# RA2A1 register map
Vendor: Renesas Electronics Corporation; Series: RA2; File version: 1.1
CPU: other r1p0, little endian, MPU, no FPU, VTOR, 2 interrupt priority bits
Registers are 8-bit, read-write, reset 0x0 unless marked. A register's access mark holds for its fields unless they carry their own. Offsets are from the block's base; [hi:lo] are bit positions; {n}, {i} and the like mark numbered series; 'fields as' and 'values as' point back to an identical list.

## CAN0 — CAN0 Module
Base 0x40050000
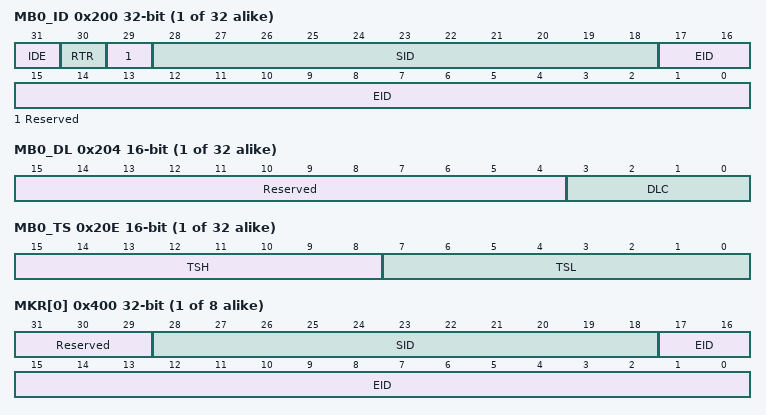
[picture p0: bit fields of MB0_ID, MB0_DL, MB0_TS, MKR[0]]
{0x200+0x10*i} MB{i}_ID (i=0..31) 32-bit reset not defined — Mailbox Register
  [31] IDE — ID Extension
    0=Standard ID; 1=Extended ID
  [30] RTR — Remote Transmission Request
    0=Data frame; 1=Remote frame
  [29] Reserved — This bit is read as 0. The write value should be 0.
  [28:18] SID — Standard ID
    0=Corresponding SID[10:0] bits are 0; 1=Corresponding SID[10:0] bits are 1
  [17:0] EID — Extended ID
    0=Corresponding EID[17:0] bits are 0; 1=Corresponding EID[17:0] bits are 1
{0x204+0x10*i} MB{i}_DL (i=0..31) 16-bit reset not defined — Mailbox Register
  [15:4] Reserved — These bits are read as 000000000000. The write value should be 000000000000.
  [3:0] DLC — Data Length Code
    0=Data length = 0 byte; 1=Data length = 1 byte; {v}=Data length = {v} bytes (v=2..7); other=others (Data length = 8 bytes)
{0x206+0x10*i} MB{i}_D0 (i=0..31) reset not defined — Mailbox Register
  [7:0] DATA0 — Data Bytes 0.DATA0 store the transmitted or received CAN message data. Transmission or reception starts from DATA0. The bit order on the CAN bus is MSB first, and transmission or reception starts from bit 7.
{0x207+0x10*i} MB{i}_D1 (i=0..31) reset not defined — Mailbox Register
  [7:0] DATA1 — Data Bytes 1DATA1 store the transmitted or received CAN message data. Transmission or reception starts from DATA0. The bit order on the CAN bus is MSB first, and transmission or reception starts from bit 7.
{0x208+0x10*i} MB{i}_D2 (i=0..31) reset not defined — Mailbox Register
  [7:0] DATA2 — Data Bytes 2DATA2 store the transmitted or received CAN message data. Transmission or reception starts from DATA0. The bit order on the CAN bus is MSB first, and transmission or reception starts from bit 7.
{0x209+0x10*i} MB{i}_D3 (i=0..31) reset not defined — Mailbox Register
  [7:0] DATA3 — Data Bytes 3DATA3 store the transmitted or received CAN message data. Transmission or reception starts from DATA0. The bit order on the CAN bus is MSB first, and transmission or reception starts from bit 7.
{0x20A+0x10*i} MB{i}_D4 (i=0..31) reset not defined — Mailbox Register
  [7:0] DATA4 — Data Bytes 4DATA4 store the transmitted or received CAN message data. Transmission or reception starts from DATA0. The bit order on the CAN bus is MSB first, and transmission or reception starts from bit 7.
{0x20B+0x10*i} MB{i}_D5 (i=0..31) reset not defined — Mailbox Register
  [7:0] DATA5 — Data Bytes 5DATA5 store the transmitted or received CAN message data. Transmission or reception starts from DATA0. The bit order on the CAN bus is MSB first, and transmission or reception starts from bit 7.
{0x20C+0x10*i} MB{i}_D6 (i=0..31) reset not defined — Mailbox Register
  [7:0] DATA6 — Data Bytes 6DATA6 store the transmitted or received CAN message data. Transmission or reception starts from DATA0. The bit order on the CAN bus is MSB first, and transmission or reception starts from bit 7.
{0x20D+0x10*i} MB{i}_D7 (i=0..31) reset not defined — Mailbox Register
  [7:0] DATA7 — Data Bytes 7DATA7 store the transmitted or received CAN message data. Transmission or reception starts from DATA0. The bit order on the CAN bus is MSB first, and transmission or reception starts from bit 7.
{0x20E+0x10*i} MB{i}_TS (i=0..31) 16-bit reset not defined — Mailbox Register
  [15:8] TSH — Time Stamp Lower ByteBits TSH[7:0] store the counter value of the time stamp when received messages are stored in the mailbox.
  [7:0] TSL — Time Stamp Higher ByteBits TSL[7:0] store the counter value of the time stamp when received messages are stored in the mailbox.
{0x400+4i} MKR[{i}] (i=0..7) 32-bit reset not defined — Mask Register
  [31:29] Reserved — These bits are read as 000. The write value should be 000.
  [28:18] SID — Standard ID
    0=Corresponding SID[10:0] bit is not compared; 1=Corresponding SID[10:0] bit is compared
  [17:0] EID — Extended ID
    0=Corresponding EID[17:0] bit is not compared; 1=Corresponding EID[17:0] bit is compared
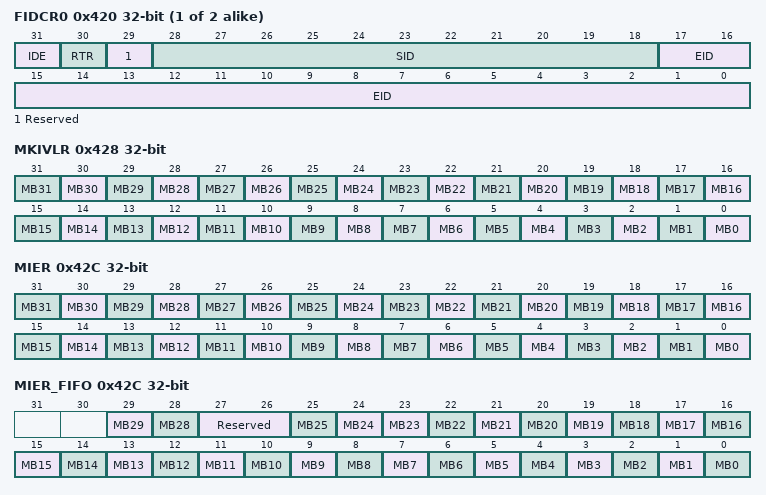
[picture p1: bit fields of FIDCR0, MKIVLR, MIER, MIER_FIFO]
{0x420+4i} FIDCR{i} (i=0..1) 32-bit reset not defined — FIFO Received ID Compare Registers
  fields as MB0_ID
0x428 MKIVLR 32-bit reset not defined — Mask Invalid Register
  [all] fields
    0=Mask valid; 1=Mask invalid
  [n] MB{n} (n=0..31) — mailbox {n} Mask Invalid
0x42C MIER 32-bit reset not defined — Mailbox Interrupt Enable Register (Normal mailbox mode)
  [all] fields
    0=Interrupt disabled; 1=Interrupt enabled
  [n] MB{n} (n=0..31) — mailbox {n} Interrupt Enable
0x42C MIER_FIFO 32-bit reset not defined (alternate view of MIER) — Mailbox Interrupt Enable Register(FIFO mailbox mode)
  [29] MB29 — Receive FIFO Interrupt Generation Timing Control
    0=Every time reception is completed; 1=When the receive FIFO becomes buffer warning by completion of reception
  [28] MB28 — Receive FIFO Interrupt Enable
    0=Interrupt disabled; 1=Interrupt enabled
  [27:26] Reserved — These bits are read as 00. The write value should be 00.
  [25] MB25 — Transmit FIFO Interrupt Generation Timing Control
    0=Every time transmission is completed; 1=When the transmit FIFO becomes empty due to completion of transmission
  [24] MB24 — Transmit FIFO Interrupt Enable
    0=Interrupt disabled; 1=Interrupt enabled
  [n] MB{n} (n=0..23) — mailbox {n} Interrupt Enable
    0=Interrupt disabled; 1=Interrupt enabled
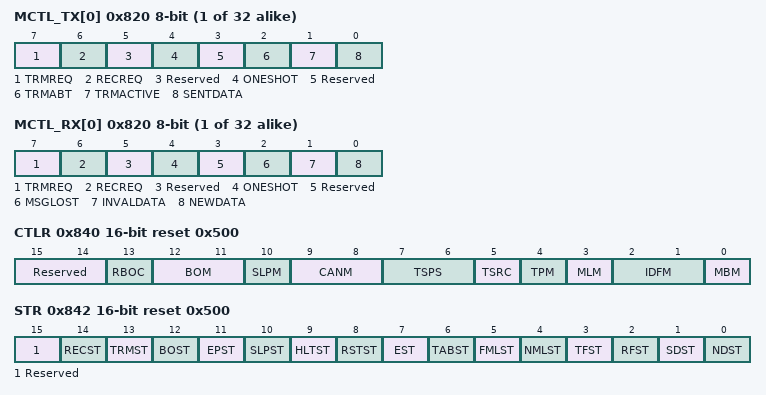
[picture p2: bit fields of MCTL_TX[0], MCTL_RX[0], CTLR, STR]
{0x820+i} MCTL_TX[{i}] (i=0..31) — Message Control Register(Transmit mode (when the TRMREQ bit is 1 and the RECREQ bit is 0))
  [7] TRMREQ — Transmit Mailbox Request
    0=Not configured for transmission; 1=Configured for transmission
  [6] RECREQ — Receive Mailbox Request
    0=Not configured for reception; 1=Configured for reception
  [5] Reserved — This bit is read as 0. The write value should be 0.
  [4] ONESHOT — One-Shot Enable
    0=One-shot reception or one-shot transmission disabled; 1=One-shot reception or one-shot transmission enabled
  [3] Reserved — This bit is read as 0. The write value should be 0.
  [2] TRMABT — Transmission Abort Complete Flag (Transmit mailbox setting enabled)
    0=Transmission has started, transmission abort failed because transmission is completed, or transmission abort is not requested; 1=Transmission abort is completed
  [1] TRMACTIVE ro — Transmission-in-Progress Status Flag (Transmit mailbox setting enabled)
    0=Transmission is pending or transmission is not requested; 1=From acceptance of transmission request to completion of transmission, or error/arbitration-lost
  [0] SENTDATA — Transmission Complete Flag
    0=Transmission is not completed; 1=Transmission is completed
{0x820+i} MCTL_RX[{i}] (i=0..31) (alternate view of MCTL_TX[{i}]) — Message Control Register( Receive mode (when the TRMREQ bit is 0 and the RECREQ bit is 1))
  [7] TRMREQ — Transmit Mailbox Request
    values as MCTL_TX[0].TRMREQ
  [6] RECREQ — Receive Mailbox Request
    0=Not configured for reception; 1=Configured for reception
  [5] Reserved — This bit is read as 0. The write value should be 0.
  [4] ONESHOT — One-Shot Enable
    values as MCTL_TX[0].ONESHOT
  [3] Reserved — This bit is read as 0. The write value should be 0.
  [2] MSGLOST — Message Lost Flag(Receive mailbox setting enabled)
    0=Message is not overwritten or overrun; 1=Message is overwritten or overrun
  [1] INVALDATA ro — Reception-in-Progress Status Flag (Receive mailbox setting enabled)
    0=Message valid; 1=Message being updated
  [0] NEWDATA — Reception Complete Flag
    0=No data has been received or 0 is written to the NEWDATA bit; 1=A new message is being stored or has been stored to the mailbox
0x840 CTLR 16-bit reset 0x500 — Control Register
  [15:14] Reserved — These bits are read as 00. The write value should be 00.
  [13] RBOC — Forcible Return From Bus-Off
    0=Nothing occurred; 1=Forcible return from bus-off
  [12:11] BOM — Bus-Off Recovery Mode
    0=Normal mode (ISO11898-1 compliant); 1=Entry to CAN halt mode automatically at bus-off entry; 2=Entry to CAN halt mode automatically at bus-off end; 3=Entry to CAN halt mode (during bus-off recovery period) by a program request
  [10] SLPM — CAN Sleep Mode
    0=Other than CAN sleep mode; 1=CAN sleep mode
  [9:8] CANM — CAN Mode of Operation Select
    0=CAN operation mode; 1=CAN reset mode; 2=CAN halt mode; 3=CAN reset mode (forcible transition)
  [7:6] TSPS — Time Stamp Prescaler Select
    0=Every bit time; 1=Every 2-bit time; 2=Every 4-bit time; 3=Every 8-bit time
  [5] TSRC — Time Stamp Counter Reset Command
    0=Nothing occurred; 1=Reset
  [4] TPM — Transmission Priority Mode Select
    0=ID priority transmit mode; 1=Mailbox number priority transmit mode
  [3] MLM — Message Lost Mode Select
    0=Overwrite mode; 1=Overrun mode
  [2:1] IDFM — ID Format Mode Select
    0=Standard ID mode.All mailboxes (including FIFO mailboxes) handle only standard Ids; 1=Extended ID mode.All mailboxes (including FIFO mailboxes) handle only extended IDs; 2=Mixed ID mode.All mailboxes (including FIFO mailboxes) handle both standard IDs and extended IDs. Standard IDs or extended IDs are specified by using the IDE bit in the corresponding mailbox in normal mailbox mode. In FIFO mailbox mode, the IDE bit in the corresponding mailbox is used for mailboxes [0] to [23], the IDE bits in FIDCR0 and FIDCR1 are used for the receive FIFO, and the IDE bit in mailbox [24] is used for the transmit FIFO.; 3=Do not use this combination
  [0] MBM — CAN Mailbox Mode Select
    0=Normal mailbox mode; 1=FIFO mailbox mode
0x842 STR 16-bit ro reset 0x500 — Status Register
  [15] Reserved — This bit is read as 0.
  [14] RECST — Receive Status Flag (receiver)
    0=Bus idle or transmission in progress; 1=Reception in progress
  [13] TRMST — Transmit Status Flag (transmitter)
    0=Bus idle or reception in progress; 1=Transmission in progress or in bus-off state
  [12] BOST — Bus-Off Status Flag
    0=Not in bus-off state; 1=In bus-off state
  [11] EPST — Error-Passive Status Flag
    0=Not in error-passive state; 1=In error-passive state
  [10] SLPST — CAN Sleep Status Flag
    0=Not in CAN sleep mode; 1=In CAN sleep mode
  [9] HLTST — CAN Halt Status Flag
    0=Not in CAN halt mode; 1=In CAN halt mode
  [8] RSTST — CAN Reset Status Flag
    0=Not in CAN reset mode; 1=In CAN reset mode
  [7] EST — Error Status Flag
    0=No error occurred; 1=Error occurred
  [6] TABST — Transmission Abort Status Flag
    0=No mailbox with TRMABT bit = 1; 1=Mailbox(es) with TRMABT bit = 1
  [5] FMLST — FIFO Mailbox Message Lost Status Flag
    0=RFMLF bit = 0; 1=RFMLF bit = 1
  [4] NMLST — Normal Mailbox Message Lost Status Flag
    0=No mailbox with MSGLOST bit = 1; 1=Mailbox(es) with MSGLOST bit = 1
  [3] TFST — Transmit FIFO Status Flag
    0=Transmit FIFO is full; 1=Transmit FIFO is not full
  [2] RFST — Receive FIFO Status Flag
    0=No message in receive FIFO (empty); 1=Message in receive FIFO
  [1] SDST — SENTDATA Status Flag
    0=No mailbox with SENTDATA bit = 1; 1=Mailbox(es) with SENTDATA bit = 1
  [0] NDST — NEWDATA Status Flag
    0=No mailbox with NEWDATA bit = 1; 1=Mailbox(es) with NEWDATA bit = 1
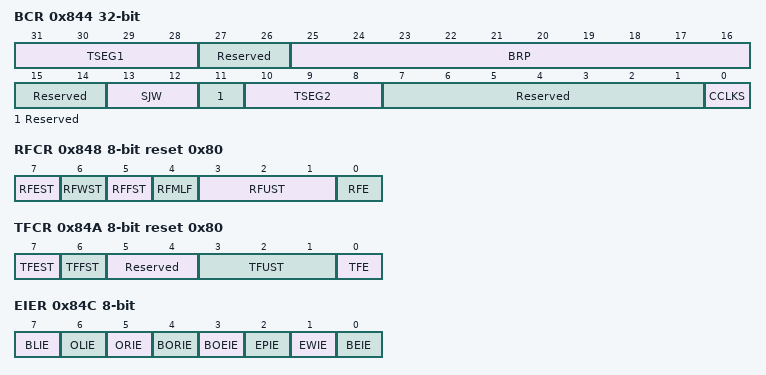
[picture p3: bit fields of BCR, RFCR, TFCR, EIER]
0x844 BCR 32-bit — Bit Configuration Register
  [31:28] TSEG1 — Time Segment 1 Control
    {v}={v+1} Tq (v=3..15); other=others (Setting prohibited)
  [27:26] Reserved — These bits are read as 00. The write value should be 00.
  [25:16] BRP — Baud Rate Prescaler select . These bits set the frequency of the CAN communication clock (fCANCLK).
  [15:14] Reserved — These bits are read as 00. The write value should be 00.
  [13:12] SJW — Resynchronization Jump Width Control
    {v}={v+1} Tq (v=0..3)
  [11] Reserved — This bit is read as 0. The write value should be 0.
  [10:8] TSEG2 — Time Segment 2 Control
    0=Setting prohibited; {v}={v+1} Tq (v=1..7)
  [7:1] Reserved — These bits are read as 0000000. The write value should be 0000000.
  [0] CCLKS — CAN Clock Source Selection
    0=PCLK (generated by the PLL clock); 1=CANMCLK (generated by the main clock)
0x848 RFCR reset 0x80 — Receive FIFO Control Register
  [7] RFEST ro — Receive FIFO Empty Status Flag
    0=Unread message in receive FIFO; 1=No unread message in receive FIFO
  [6] RFWST ro — Receive FIFO Buffer Warning Status Flag
    0=Receive FIFO is not buffer warning; 1=Receive FIFO is buffer warning (3 unread messages)
  [5] RFFST ro — Receive FIFO Full Status Flag
    0=Receive FIFO is not full; 1=Receive FIFO is full (4 unread messages)
  [4] RFMLF — Receive FIFO Message Lost Flag
    0=No receive FIFO message lost has occurred; 1=Receive FIFO message lost has occurred
  [3:1] RFUST ro — Receive FIFO Unread Message Number Status
    0=No unread message; 1=1 unread message; 2=2 unread messages; 3=3 unread messages; 4=4 unread messages; other=others (Setting prohibited)
  [0] RFE — Receive FIFO Enable
    0=Receive FIFO disabled; 1=Receive FIFO enabled
0x849 RFPCR wo reset not defined — Receive FIFO Pointer Control Register
  [7:0] RFPCR — The CPU-side pointer for the receive FIFO is incremented by writing FFh to RFPCR.
0x84A TFCR reset 0x80 — Transmit FIFO Control Register
  [7] TFEST ro — Transmit FIFO Empty Status
    0=Unsent message in transmit FIFO; 1=No unsent message in transmit FIFO
  [6] TFFST ro — Transmit FIFO Full Status
    0=Transmit FIFO is not full; 1=Transmit FIFO is full (4 unsent messages)
  [5:4] Reserved — These bits are read as 00. The write value should be 00.
  [3:1] TFUST ro — Transmit FIFO Unsent Message Number Status
    0=No unsent message; 1=1 unsent message; 2=2 unsent messages; 3=3 unsent messages; 4=4 unsent messages; other=others (Setting prohibited)
  [0] TFE — Transmit FIFO Enable
    0=Transmit FIFO disabled; 1=Transmit FIFO enabled
0x84B TFPCR wo reset not defined — Transmit FIFO Pointer Control Register
  [7:0] TFPCR — The CPU-side pointer for the transmit FIFO is incremented by writing FFh to TFPCR.
0x84C EIER — Error Interrupt Enable Register
  [7] BLIE — Bus Lock Interrupt Enable
    0=Bus lock interrupt disabled; 1=Bus lock interrupt enabled
  [6] OLIE — Overload Frame Transmit Interrupt Enable
    0=Overload frame transmit interrupt disabled; 1=Overload frame transmit interrupt enabled
  [5] ORIE — Overrun Interrupt Enable
    0=Receive overrun interrupt disabled; 1=Receive overrun interrupt enabled
  [4] BORIE — Bus-Off Recovery Interrupt Enable
    0=Bus-off recovery interrupt disabled; 1=Bus-off recovery interrupt enabled
  [3] BOEIE — Bus-Off Entry Interrupt Enable
    0=Bus-off entry interrupt disabled; 1=Bus-off entry interrupt enabled
  [2] EPIE — Error-Passive Interrupt Enable
    0=Error-passive interrupt disabled; 1=Error-passive interrupt enabled
  [1] EWIE — Error-Warning Interrupt Enable
    0=Error-warning interrupt disabled; 1=Error-warning interrupt enabled
  [0] BEIE — Bus Error Interrupt Enable
    0=Bus error interrupt disabled; 1=Bus error interrupt enabled
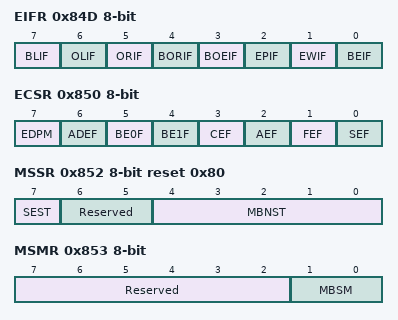
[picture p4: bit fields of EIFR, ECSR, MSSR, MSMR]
0x84D EIFR — Error Interrupt Factor Judge Register
  [7] BLIF — Bus Lock Detect Flag
    0=No bus lock detected; 1=Bus lock detected
  [6] OLIF — Overload Frame Transmission Detect Flag
    0=No overload frame transmission detected; 1=Overload frame transmission detected
  [5] ORIF — Receive Overrun Detect Flag
    0=No receive overrun detected; 1=Receive overrun detected
  [4] BORIF — Bus-Off Recovery Detect Flag
    0=No bus-off recovery detected; 1=Bus-off recovery detected
  [3] BOEIF — Bus-Off Entry Detect Flag
    0=No bus-off entry detected; 1=Bus-off entry detected
  [2] EPIF — Error-Passive Detect Flag
    0=No error-passive detected; 1=Error-passive detected
  [1] EWIF — Error-Warning Detect Flag
    0=No error-warning detected; 1=Error-warning detected
  [0] BEIF — Bus Error Detect Flag
    0=No bus error detected; 1=Bus error detected
0x84E RECR ro — Receive Error Count Register
  [7:0] RECR — Receive error count functionRECR increments or decrements the counter value according to the error status of the CAN module during reception.
0x84F TECR ro — Transmit Error Count Register
  [7:0] TECR — Transmit error count functionTECR increments or decrements the counter value according to the error status of the CAN module during transmission.
0x850 ECSR — Error Code Store Register
  [7] EDPM — Error Display Mode Select
    0=Output of first detected error code; 1=Output of accumulated error code
  [6] ADEF — ACK Delimiter Error Flag
    0=No ACK delimiter error detected; 1=ACK delimiter error detected
  [5] BE0F — Bit Error (dominant) Flag
    0=No bit error (dominant) detected; 1=Bit error (dominant) detected
  [4] BE1F — Bit Error (recessive) Flag
    0=No bit error (recessive) detected; 1=Bit error (recessive) detected
  [3] CEF — CRC Error Flag
    0=No CRC error detected; 1=CRC error detected
  [2] AEF — ACK Error Flag
    0=No ACK error detected; 1=ACK error detected
  [1] FEF — Form Error Flag
    0=No form error detected; 1=Form error detected
  [0] SEF — Stuff Error Flag
    0=No stuff error detected; 1=Stuff error detected
0x851 CSSR reset not defined — Channel Search Support Register
  [7:0] CSSR — When the value for the channel search is input, the channel number is output to MSSR.
0x852 MSSR ro reset 0x80 — Mailbox Search Status Register
  [7] SEST — Search Result Status
    0=Search result found; 1=No search result
  [6:5] Reserved — These bits are read as 00.
  [4:0] MBNST — Search Result Mailbox Number Status These bits output the smallest mailbox number that is searched in each mode of MSMR.
0x853 MSMR — Mailbox Search Mode Register
  [7:2] Reserved — These bits are read as 000000. The write value should be 000000.
  [1:0] MBSM — Mailbox Search Mode Select
    0=Receive mailbox search mode; 1=Transmit mailbox search mode; 2=Message lost search mode; 3=Channel search mode
0x854 TSR 16-bit ro — Time Stamp Register
  [15:0] TSR — Free-running counter value for the time stamp function
0x856 AFSR 16-bit reset not defined — Acceptance Filter Support Register
  [15:0] AFSR — After the standard ID of a received message is written, the value converted for data table search can be read.
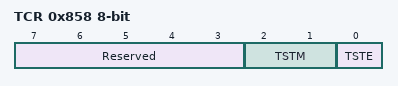
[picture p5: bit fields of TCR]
0x858 TCR — Test Control Register
  [7:3] Reserved — These bits are read as 00000. The write value should be 00000.
  [2:1] TSTM — CAN Test Mode Select
    0=Other than CAN test mode; 1=Listen-only mode; 2=Self-test mode 0 (external loopback); 3=Self-test mode 1 (internal loopback)
  [0] TSTE — CAN Test Mode Enable
    0=CAN test mode disabled; 1=CAN test mode enabled
